# NM1330AE_v1 register map
File version: 1.0
Registers are 32-bit, read-write, reset 0x0 unless marked. A register's access mark holds for its fields unless they carry their own. Offsets are from the block's base; [hi:lo] are bit positions.

## WDT — WDT Register Map
Base 0x40004000
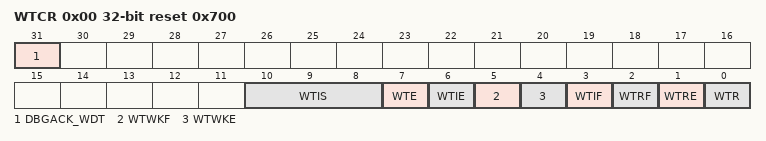
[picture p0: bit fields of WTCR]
0x00 WTCR reset 0x700 — Watchdog Timer Control Register
  [31] DBGACK_WDT — ICE Debug Mode Acknowledge Disable Control (Write Protect). WDT up counter will keep going no matter CPU is held by ICE or not.
    0=ICE debug mode acknowledgement effects WDT counting; 1=ICE debug mode acknowledgement Disabled
  [10:8] WTIS — Watchdog Timer Time-out Interval Selection (Write Protect). These three bits select the time-out interval period for the WDT.
    0=24 *TWDT; 1=26 *TWDT; 2=28 *TWDT; 3=210 *TWDT; 4=212 *TWDT; 5=214 *TWDT; 6=216 *TWDT; 7=218 *TWDT
  [7] WTE — Watchdog Timer Enable Control (Write Protect)
    0=WDT Disabled. (This action will reset the internal up counter value.); 1=WDT Enabled
  [6] WTIE — Watchdog Timer Time-out Interrupt Enable Control (Write Protect). If this bit is enabled, the WDT time-out interrupt signal is generated and inform to CPU.
    0=WDT time-out interrupt Disabled; 1=WDT time-out interrupt Enabled
  [5] WTWKF — Watchdog Timer Time-out Wake-up Flag. This bit indicates the interrupt wake-up flag status of WDT. Note: This bit is cleared by writing 1 to it.
    0=WDT does not cause chip wake-up; 1=Chip wake-up from Idle or Power-down mode if WDT time-out interrupt signal generated
  [4] WTWKE — Watchdog Timer Time-out Wake-up Function Control (Write Protect). If this bit is set to 1, while WTIF is generated to 1 and WTIE enabled, the WDT time-out interrupt signal will generate a wake-up trigger event to chip. Note: Chip can be woken-up by WDT time-out interrupt signal generated only if WDT clock source is selected to 10 kHz oscillator.
    0=Wake-up trigger event Disabled if WDT time-out interrupt signal generated; 1=Wake-up trigger event Enabled if WDT time-out interrupt signal generated
  [3] WTIF — Watchdog Timer Time-out Interrupt Flag. This bit will set to 1 while WDT up counter value reaches the selected WDT time-out interval. Note: This bit is cleared by writing 1 to it.
    0=WDT time-out interrupt did not occur; 1=WDT time-out interrupt occurred
  [2] WTRF — Watchdog Timer Time-out Reset Flag. This bit indicates the system has been reset by WDT time-out reset or not. Note: This bit is cleared by writing 1 to it.
    0=WDT time-out reset did not occur; 1=WDT time-out reset occurred
  [1] WTRE — Watchdog Timer Time-out Reset Enable Control (Write Protect). Setting this bit will enable the WDT time-out reset function If the WDT up counter value has not been cleared after the specific WDT reset delay period expires. Note: Fixed 1024 * TWDT delay period on M05xxBN. Selectable 3/18/130/1026 * TWDT delay period controlled by WTRDSEL on M05xxDE.
    0=WDT time-out reset function Disabled; 1=WDT time-out reset function Enabled
  [0] WTR — Reset Watchdog Timer Up Counter (Write Protect). Note: This bit will be automatically cleared by hardware.
    0=No effect; 1=Reset the internal 18-bit WDT up counter value
0x04 WTCRALT — Watchdog Timer Alternative Control Register
  [1:0] WTRDSEL — Watchdog Timer Reset Delay Selection (Write Protect). When WDT time-out happened, software has a time named WDT Reset Delay Period to clear WDT counter to prevent WDT time-out reset happened. Software can select a suitable value of WDT Reset Delay Period for different WDT time-out period. Note: This register will be reset to 0 if WDT time-out reset happened.
    0=Watchdog Timer Reset Delay Period is 1026 * WDT_CLK; 1=Watchdog Timer Reset Delay Period is 130* WDT_CLK; 2=Watchdog Timer Reset Delay Period is 18 * WDT_CLK; 3=Watchdog Timer Reset Delay Period is 3 * WDT_CLK

## WWDT — WWDT Register Map
Base 0x40004100
0x00 WWDTRLD wo — Window Watchdog Timer Reload Counter Register
  [31:0] WWDTRLD — WWDT Reload Counter Register. Writing 0x00005AA5 to this register will reload the WWDT counter value to 0x3F. Note: Software can only write WWDTRLD to reload WWDT counter value whencurrent WWDT counter value between 0 and WINCMP. If software writes WWDTRLD when current WWDT counter value is larger than WINCMP, WWDT reset signal will generate immediately.
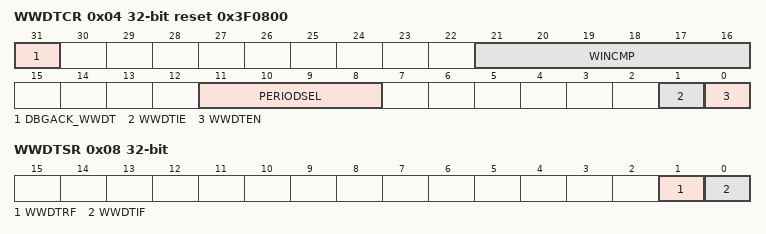
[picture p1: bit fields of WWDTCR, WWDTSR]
0x04 WWDTCR reset 0x3F0800 — Window Watchdog Timer Control Register
  [31] DBGACK_WWDT — ICE Debug Mode Acknowledge Disable Control. WWDT down counter will keep going no matter CPU is held by ICE or not.
    0=ICE debug mode acknowledgement effects WWDT counting; 1=ICE debug mode acknowledgement Disabled
  [21:16] WINCMP — WWDT Window Compare Register. Set this register to adjust the valid reload window. Note: Software can only write WWDTRLD to reload WWDT counter value when current WWDT counter value between 0 and WINCMP. If Software writes WWDTRLD when current WWDT counter value larger than WINCMP, WWDT reset signal will generate immediately.
  [11:8] PERIODSEL — WWDT Counter Prescale Period Selection
    0=Pre-scale is 1; Max time-out period is 1 * 64 * TWWDT; 1=Pre-scale is 2; Max time-out period is 2 * 64 * TWWDT; 2=Pre-scale is 4; Max time-out period is 4 * 64 * TWWDT; 3=Pre-scale is 8; Max time-out period is 8 * 64 * TWWDT; 4=Pre-scale is 16; Max time-out period is 16 * 64 * TWWDT; 5=Pre-scale is 32; Max time-out period is 32 * 64 * TWWDT; 6=Pre-scale is 64; Max time-out period is 64 * 64 * TWWDT; 7=Pre-scale is 128; Max time-out period is 128 * 64 * TWWDT; 8=Pre-scale is 192; Max time-out period is 192 * 64 * TWWDT; 9=Pre-scale is 256; Max time-out period is 256 * 64 * TWWDT; 10=Pre-scale is 384; Max time-out period is 384 * 64 * TWWDT; 11=Pre-scale is 512; Max time-out period is 512 * 64 * TWWDT; 12=Pre-scale is 768; Max time-out period is 768 * 64 * TWWDT; 13=Pre-scale is 1024; Max time-out period is 1024 * 64 * TWWDT; 14=Pre-scale is 1536; Max time-out period is 1536 * 64 * TWWDT; 15=Pre-scale is 2048; Max time-out period is 2048 * 64 * TWWDT
  [1] WWDTIE — WWDT Interrupt Enable Control. If this bit is enabled, the WWDT counter compare match interrupt signal is generated and inform to CPU.
    0=WWDT counter compare match interrupt Disabled; 1=WWDT counter compare match interrupt Enabled
  [0] WWDTEN — WWDT Enable Control
    0=WWDT counter is stopped; 1=WWDT counter is starting counting
0x08 WWDTSR — Window Watchdog Timer Status Register
  [1] WWDTRF — WWDT Timer-out Reset Flag. This bit indicates the system has been reset by WWDT time-out reset or not. Note: This bit is cleared by writing 1 to it.
    0=WWDT time-out reset did not occur; 1=WWDT time-out reset occurred
  [0] WWDTIF — WWDT Compare Match Interrupt Flag. This bit indicates the interrupt flag status of WWDT while WWDT counter value matches WINCMP value. Note: This bit is cleared by writing 1 to it.
    0=No effect; 1=WWDT counter value matches WINCMP value
0x0C WWDTCVR ro reset 0x3F — Window Watchdog Timer Counter Value Register
  [5:0] WWDTCVAL — WWDT Counter Value. WWDTCVAL will be updated continuously to monitor 6-bit down counter value.
